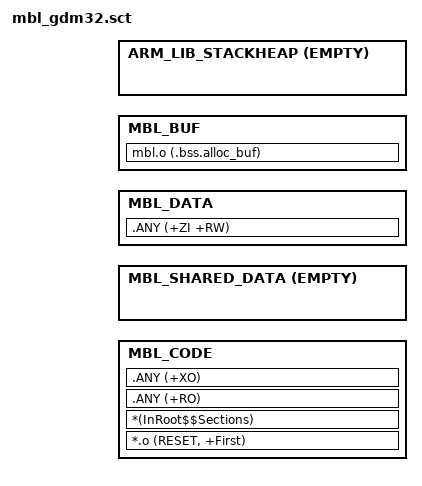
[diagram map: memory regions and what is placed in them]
#! armclang --target=arm-arm-none-eabi -march=armv8-m.main -E -xc -I ../../../config -I ../../../../Platform/GD32G5x3/armclang -I ../../MBL

/*
 * Copyright (c) 2017-2018 ARM Limited. All rights reserved.
 *
 * Licensed under the Apache License, Version 2.0 (the "License");
 * you may not use this file except in compliance with the License.
 * You may obtain a copy of the License at
 *
 *     http://www.apache.org/licenses/LICENSE-2.0
 *
 * Unless required by applicable law or agreed to in writing, software
 * distributed under the License is distributed on an "AS IS" BASIS,
 * WITHOUT WARRANTIES OR CONDITIONS OF ANY KIND, either express or implied.
 * See the License for the specific language governing permissions and
 * limitations under the License.
 */

#include "../../MBL/mbl_region.h"

LR_CODE_1 MBL_CODE_START MBL_CODE_SIZE {

    MBL_CODE +0{
           *.o (RESET, +First)
   *(InRoot$$Sections)
   .ANY (+RO)
   .ANY (+XO)
    }

    MBL_SHARED_DATA MBL_SHARED_DATA_START ALIGN 8 EMPTY MBL_SHARED_DATA_SIZE {
    }

    MBL_DATA MBL_DATA_START MBL_DATA_SIZE{
        .ANY (+ZI +RW)
    }

    MBL_BUF +0 ALIGN 8 {
        mbl.o (.bss.alloc_buf)
    }

    ARM_LIB_STACKHEAP +0 ALIGN 16 EMPTY MBL_MSP_STACK_SIZE {
    }

}

